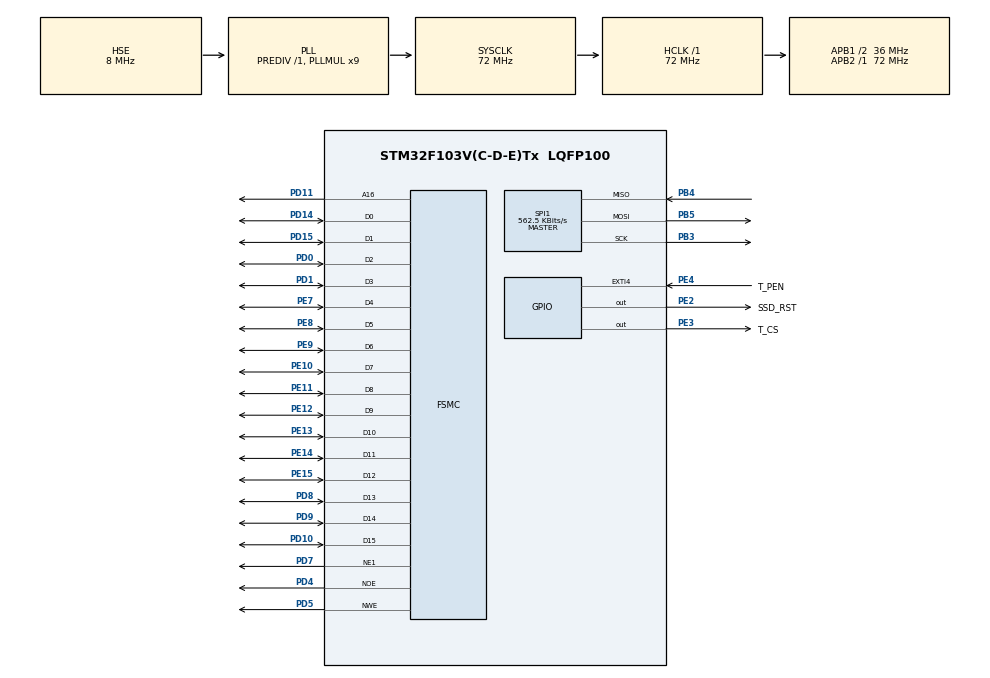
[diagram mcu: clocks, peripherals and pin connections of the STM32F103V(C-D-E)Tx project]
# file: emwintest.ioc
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FSMC.AddressSetupTime1=0x2
FSMC.BusTurnAroundDuration1=0x0
FSMC.DataSetupTime1=0x0a
Mcu.Family=STM32F1
Mcu.Name=STM32F103V(C-D-E)Tx
Mcu.Package=LQFP100
NVIC.PriorityGroup=NVIC_PRIORITYGROUP_4
OSC_IN.Mode=HSE-External-Oscillator
OSC_IN.Signal=RCC_OSC_IN
OSC_OUT.Mode=HSE-External-Oscillator
OSC_OUT.Signal=RCC_OSC_OUT
PA13.Mode=Serial_Wire
PA13.Signal=SYS_JTMS-SWDIO
PA14.Mode=Serial_Wire
PA14.Signal=SYS_JTCK-SWCLK
PB3.Mode=Full_Duplex_Master
PB3.Signal=SPI1_SCK
PB4.Mode=Full_Duplex_Master
PB4.Signal=SPI1_MISO
PB5.Mode=Full_Duplex_Master
PB5.Signal=SPI1_MOSI
PD0.Mode=16b-d1
PD0.Signal=FSMC_D2
PD1.Mode=16b-d1
PD1.Signal=FSMC_D3
PD10.Mode=16b-d1
PD10.Signal=FSMC_D15
PD11.Mode=A16_1
PD11.Signal=FSMC_A16
PD14.Mode=16b-d1
PD14.Signal=FSMC_D0
PD15.Mode=16b-d1
PD15.Signal=FSMC_D1
PD4.Mode=Lcd1
PD4.Signal=FSMC_NOE
PD5.Mode=Lcd1
PD5.Signal=FSMC_NWE
PD7.Mode=NorPsramChipSelect1_1
PD7.Signal=FSMC_NE1
PD8.Mode=16b-d1
PD8.Signal=FSMC_D13
PD9.Mode=16b-d1
PD9.Signal=FSMC_D14
PE10.Mode=16b-d1
PE10.Signal=FSMC_D7
PE11.Mode=16b-d1
PE11.Signal=FSMC_D8
PE12.Mode=16b-d1
PE12.Signal=FSMC_D9
PE13.Mode=16b-d1
PE13.Signal=FSMC_D10
PE14.Mode=16b-d1
PE14.Signal=FSMC_D11
PE15.Mode=16b-d1
PE15.Signal=FSMC_D12
PE2.GPIO_Label=SSD_RST
PE2.Signal=GPIO_Output
PE3.GPIO_Label=T_CS
PE3.Signal=GPIO_Output
PE4.GPIO_Label=T_PEN
PE4.GPIO_ModeDefaultEXTI=GPIO_MODE_EVT_FALLING
PE4.GPIO_PuPd=GPIO_PULLUP
PE4.Signal=GPXTI4
PE7.Mode=16b-d1
PE7.Signal=FSMC_D4
PE8.Mode=16b-d1
PE8.Signal=FSMC_D5
PE9.Mode=16b-d1
PE9.Signal=FSMC_D6
ProjectManager.HeapSize=0x200
ProjectManager.StackSize=0x400
ProjectManager.TargetToolchain=MDK-ARM V5
RCC.AHBFreq_Value=72000000
RCC.APB1CLKDivider=RCC_HCLK_DIV2
RCC.APB1Freq_Value=36000000
RCC.APB1TimFreq_Value=72000000
RCC.APB2Freq_Value=72000000
RCC.APB2TimFreq_Value=72000000
RCC.HCLKFreq_Value=72000000
RCC.PLLMUL=RCC_PLL_MUL9
RCC.PLLSourceVirtual=RCC_PLLSOURCE_HSE
RCC.SYSCLKFreq_VALUE=72000000
RCC.SYSCLKSource=RCC_SYSCLKSOURCE_PLLCLK
RCC.USBFreq_Value=72000000
SPI1.BaudRatePrescaler=SPI_BAUDRATEPRESCALER_128
SPI1.CalculateBaudRate=562.5 KBits/s
SPI1.Direction=SPI_DIRECTION_2LINES
SPI1.Mode=SPI_MODE_MASTER
SPI1.VirtualType=VM_MASTER
VP_CRC_VS_CRC.Mode=CRC_Activate
board=custom

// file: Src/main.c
/* USER CODE BEGIN Header */
/**
  ******************************************************************************
  * @file           : main.c
  * @brief          : Main program body
  ******************************************************************************
  * @attention
  *
  * <h2><center>&copy; Copyright (c) 2019 STMicroelectronics.
  * All rights reserved.</center></h2>
  *
  * This software component is licensed by ST under BSD 3-Clause license,
  * the "License"; You may not use this file except in compliance with the
  * License. You may obtain a copy of the License at:
  *                        opensource.org/licenses/BSD-3-Clause
  *
  ******************************************************************************
  */
/* USER CODE END Header */
#include "main.h"
#include "crc.h"
#include "spi.h"
#include "gpio.h"
#include "fsmc.h"

/* USER CODE BEGIN Includes */
#include "GUI.h"
#include "xpt2046.h"
#include "GUI_Touch_Calibrate.h"
/* USER CODE END Includes */

/* USER CODE BEGIN PV */
  int X;
  int Y;
/* USER CODE END PV */

void SystemClock_Config(void);

int main(void)
{

  /* MCU Configuration--------------------------------------------------------*/

  /* Reset of all peripherals, Initializes the Flash interface and the Systick. */
  HAL_Init();

  /* Configure the system clock */
  SystemClock_Config();

  /* Initialize all configured peripherals */
  MX_GPIO_Init();
  MX_FSMC_Init();
  MX_CRC_Init();
  MX_SPI1_Init();
  /* USER CODE BEGIN 2 */
	GUI_Init();

	GUI_SetBkColor(GUI_GREEN);
	GUI_Clear();

	exec_calibration(480,272);

  /* USER CODE END 2 */

  /* Infinite loop */
  while (1)
  {

    /* USER CODE BEGIN 3 */
		X = GUI_TOUCH_GetxPhys();
		Y = GUI_TOUCH_GetyPhys();
		GUI_TOUCH_StoreState(X,Y);
		HAL_Delay(50);

  }
  /* USER CODE END 3 */
}

void SystemClock_Config(void)
{
  RCC_OscInitTypeDef RCC_OscInitStruct = {0};
  RCC_ClkInitTypeDef RCC_ClkInitStruct = {0};

  /** Initializes the RCC Oscillators according to the specified parameters
  * in the RCC_OscInitTypeDef structure.
  */
  RCC_OscInitStruct.OscillatorType = RCC_OSCILLATORTYPE_HSE;
  RCC_OscInitStruct.HSEState = RCC_HSE_ON;
  RCC_OscInitStruct.HSEPredivValue = RCC_HSE_PREDIV_DIV1;
  RCC_OscInitStruct.HSIState = RCC_HSI_ON;
  RCC_OscInitStruct.PLL.PLLState = RCC_PLL_ON;
  RCC_OscInitStruct.PLL.PLLSource = RCC_PLLSOURCE_HSE;
  RCC_OscInitStruct.PLL.PLLMUL = RCC_PLL_MUL9;
  if (HAL_RCC_OscConfig(&RCC_OscInitStruct) != HAL_OK)
  {
    Error_Handler();
  }
  /** Initializes the CPU, AHB and APB buses clocks
  */
  RCC_ClkInitStruct.ClockType = RCC_CLOCKTYPE_HCLK|RCC_CLOCKTYPE_SYSCLK
                              |RCC_CLOCKTYPE_PCLK1|RCC_CLOCKTYPE_PCLK2;
  RCC_ClkInitStruct.SYSCLKSource = RCC_SYSCLKSOURCE_PLLCLK;
  RCC_ClkInitStruct.AHBCLKDivider = RCC_SYSCLK_DIV1;
  RCC_ClkInitStruct.APB1CLKDivider = RCC_HCLK_DIV2;
  RCC_ClkInitStruct.APB2CLKDivider = RCC_HCLK_DIV1;

  if (HAL_RCC_ClockConfig(&RCC_ClkInitStruct, FLASH_LATENCY_2) != HAL_OK)
  {
    Error_Handler();
  }
}

void Error_Handler(void)
{
}

/************************ (C) COPYRIGHT STMicroelectronics *****END OF FILE****/
